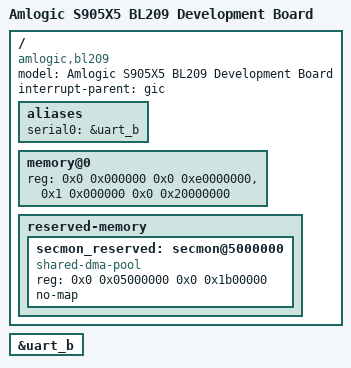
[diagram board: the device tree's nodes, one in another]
// SPDX-License-Identifier: (GPL-2.0+ OR MIT)
/*
 * Copyright (c) 2025 Amlogic, Inc. All rights reserved.
 */

/dts-v1/;

#include "amlogic-s6.dtsi"
/ {
	model = "Amlogic S905X5 BL209 Development Board";
	compatible = "amlogic,bl209", "amlogic,s6";
	interrupt-parent = <&gic>;
	#address-cells = <2>;
	#size-cells = <2>;

	aliases {
		serial0 = &uart_b;
	};

	memory@0 {
		device_type = "memory";
		reg = <0x0 0x000000 0x0 0xe0000000>,
		      <0x1 0x000000 0x0 0x20000000>;
	};

	reserved-memory {
		#address-cells = <2>;
		#size-cells = <2>;
		ranges;

		/* 27 MiB reserved for ARM Trusted Firmware */
		secmon_reserved: secmon@5000000 {
			compatible = "shared-dma-pool";
			reg = <0x0 0x05000000 0x0 0x1b00000>;
			no-map;
		};
	};
};

&uart_b {
	status = "okay";
};
